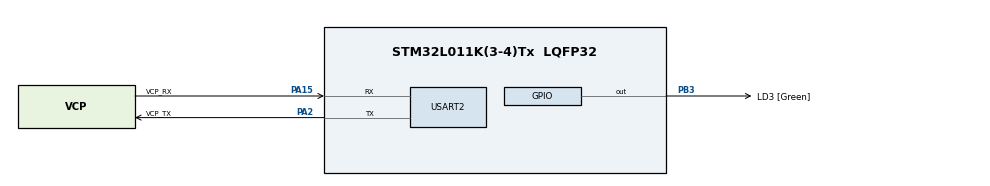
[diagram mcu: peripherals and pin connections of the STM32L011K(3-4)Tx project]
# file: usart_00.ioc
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Dma.Request0=USART2_RX
Dma.Request1=USART2_TX
Dma.USART2_RX.0.Direction=DMA_PERIPH_TO_MEMORY
Dma.USART2_RX.0.Instance=DMA1_Channel3
Dma.USART2_RX.0.MemDataAlignment=DMA_MDATAALIGN_BYTE
Dma.USART2_RX.0.MemInc=DMA_MINC_ENABLE
Dma.USART2_RX.0.Mode=DMA_NORMAL
Dma.USART2_RX.0.PeriphDataAlignment=DMA_PDATAALIGN_BYTE
Dma.USART2_RX.0.PeriphInc=DMA_PINC_DISABLE
Dma.USART2_RX.0.Priority=DMA_PRIORITY_LOW
Dma.USART2_TX.1.Direction=DMA_MEMORY_TO_PERIPH
Dma.USART2_TX.1.Instance=DMA1_Channel2
Dma.USART2_TX.1.MemDataAlignment=DMA_MDATAALIGN_BYTE
Dma.USART2_TX.1.MemInc=DMA_MINC_ENABLE
Dma.USART2_TX.1.Mode=DMA_NORMAL
Dma.USART2_TX.1.PeriphDataAlignment=DMA_PDATAALIGN_BYTE
Dma.USART2_TX.1.PeriphInc=DMA_PINC_DISABLE
Dma.USART2_TX.1.Priority=DMA_PRIORITY_LOW
Mcu.Family=STM32L0
Mcu.Name=STM32L011K(3-4)Tx
Mcu.Package=LQFP32
NVIC.DMA1_Channel2_3_IRQn=true\:0\:0\:false\:false\:true\:false
PA13.GPIO_Label=TMS
PA13.Mode=Serial_Wire
PA13.Signal=SYS_SWDIO
PA14.GPIO_Label=TCK
PA14.Mode=Serial_Wire
PA14.Signal=SYS_SWCLK
PA15.GPIO_Label=VCP_RX
PA15.Mode=Asynchronous
PA15.Signal=USART2_RX
PA2.GPIO_Label=VCP_TX
PA2.Mode=Asynchronous
PA2.Signal=USART2_TX
PB3.GPIO_Label=LD3 [Green]
PB3.Signal=GPIO_Output
PC14-OSC32_IN.Mode=LSE-External-Oscillator
PC14-OSC32_IN.Signal=RCC_OSC32_IN
PC15-OSC32_OUT.Mode=LSE-External-Oscillator
PC15-OSC32_OUT.Signal=RCC_OSC32_OUT
ProjectManager.HeapSize=0x200
ProjectManager.StackSize=0x400
ProjectManager.TargetToolchain=Makefile
RCC.AHBFreq_Value=4194000
RCC.APB1Freq_Value=4194000
RCC.APB1TimFreq_Value=4194000
RCC.APB2Freq_Value=4194000
RCC.APB2TimFreq_Value=4194000
RCC.HCLKFreq_Value=4194000
RCC.HSE_VALUE=8000000
RCC.HSI16_VALUE=16000000
RCC.HSI48_VALUE=48000000
RCC.HSI_VALUE=16000000
RCC.MSIClockRange=RCC_MSIRANGE_6
RCC.MSI_VALUE=4194000
RCC.PLLMUL=RCC_PLLMUL_4
RCC.SYSCLKFreq_VALUE=4194000
RCC.VCOOutputFreq_Value=64000000
USART2.VirtualMode-Asynchronous=VM_ASYNC
board=NUCLEO-L011K4

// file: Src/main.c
/**
  ******************************************************************************
  * @file           : main.c
  * @brief          : Main program body
  ******************************************************************************
  ** This notice applies to any and all portions of this file
  * that are not between comment pairs USER CODE BEGIN and
  * USER CODE END. Other portions of this file, whether
  * inserted by the user or by software development tools
  * are owned by their respective copyright owners.
  *
  * COPYRIGHT(c) 2018 STMicroelectronics
  *
  * Redistribution and use in source and binary forms, with or without modification,
  * are permitted provided that the following conditions are met:
  *   1. Redistributions of source code must retain the above copyright notice,
  *      this list of conditions and the following disclaimer.
  *   2. Redistributions in binary form must reproduce the above copyright notice,
  *      this list of conditions and the following disclaimer in the documentation
  *      and/or other materials provided with the distribution.
  *   3. Neither the name of STMicroelectronics nor the names of its contributors
  *      may be used to endorse or promote products derived from this software
  *      without specific prior written permission.
  *
  * THIS SOFTWARE IS PROVIDED BY THE COPYRIGHT HOLDERS AND CONTRIBUTORS "AS IS"
  * AND ANY EXPRESS OR IMPLIED WARRANTIES, INCLUDING, BUT NOT LIMITED TO, THE
  * IMPLIED WARRANTIES OF MERCHANTABILITY AND FITNESS FOR A PARTICULAR PURPOSE ARE
  * DISCLAIMED. IN NO EVENT SHALL THE COPYRIGHT HOLDER OR CONTRIBUTORS BE LIABLE
  * FOR ANY DIRECT, INDIRECT, INCIDENTAL, SPECIAL, EXEMPLARY, OR CONSEQUENTIAL
  * DAMAGES (INCLUDING, BUT NOT LIMITED TO, PROCUREMENT OF SUBSTITUTE GOODS OR
  * SERVICES; LOSS OF USE, DATA, OR PROFITS; OR BUSINESS INTERRUPTION) HOWEVER
  * CAUSED AND ON ANY THEORY OF LIABILITY, WHETHER IN CONTRACT, STRICT LIABILITY,
  * OR TORT (INCLUDING NEGLIGENCE OR OTHERWISE) ARISING IN ANY WAY OUT OF THE USE
  * OF THIS SOFTWARE, EVEN IF ADVISED OF THE POSSIBILITY OF SUCH DAMAGE.
  *
  ******************************************************************************
  */
#include "main.h"

/* USER CODE BEGIN Includes */
#include "stdlib.h"
#include "string.h"
#include "tinyprintf.h"
/* USER CODE END Includes */

/* USER CODE BEGIN PV */
/* Private variables ---------------------------------------------------------*/
//uint8_t *str;
//uint32_t size_of_str;
/* USER CODE END PV */

static void LL_Init(void);
void SystemClock_Config(void);
static void MX_GPIO_Init(void);
static void MX_DMA_Init(void);
static void MX_USART2_UART_Init(void);

/* USER CODE BEGIN PFP */
/* Private function prototypes -----------------------------------------------*/
/* USER CODE END PFP */

int main(void)
{

  /* MCU Configuration----------------------------------------------------------*/

  /* Reset of all peripherals, Initializes the Flash interface and the Systick. */
  LL_Init();

  /* Configure the system clock */
  SystemClock_Config();

  /* Initialize all configured peripherals */
  MX_GPIO_Init();
  MX_DMA_Init();
  MX_USART2_UART_Init();
  /* USER CODE BEGIN 2 */
  uart_print_init();
  tfp_printf ("tfp_printf testing..!!\n");
  uint32_t a = 100;
  tfp_printf ("Int : %d, Hex : %04x\n", a ,a);
  /* USER CODE END 2 */

  /* Infinite loop */
  /* USER CODE BEGIN WHILE */
  while (1)
  {
//    tfp_printf("In while 1.. Code not stuck..!!\n");
  /* USER CODE END WHILE */

  }

}
static void LL_Init(void)
{

  LL_APB2_GRP1_EnableClock(LL_APB2_GRP1_PERIPH_SYSCFG);
  LL_APB1_GRP1_EnableClock(LL_APB1_GRP1_PERIPH_PWR);

  /* System interrupt init*/
  /* SVC_IRQn interrupt configuration */
  NVIC_SetPriority(SVC_IRQn, 0);
  /* PendSV_IRQn interrupt configuration */
  NVIC_SetPriority(PendSV_IRQn, 0);
  /* SysTick_IRQn interrupt configuration */
  NVIC_SetPriority(SysTick_IRQn, 0);

}

void SystemClock_Config(void)
{

  LL_FLASH_SetLatency(LL_FLASH_LATENCY_0);

  if(LL_FLASH_GetLatency() != LL_FLASH_LATENCY_0)
  {
  Error_Handler();
  }
  LL_PWR_SetRegulVoltageScaling(LL_PWR_REGU_VOLTAGE_SCALE1);

  LL_RCC_MSI_Enable();

   /* Wait till MSI is ready */
  while(LL_RCC_MSI_IsReady() != 1)
  {

  }
  LL_RCC_MSI_SetRange(LL_RCC_MSIRANGE_6);

  LL_RCC_MSI_SetCalibTrimming(0);

  LL_RCC_SetAHBPrescaler(LL_RCC_SYSCLK_DIV_1);

  LL_RCC_SetAPB1Prescaler(LL_RCC_APB1_DIV_1);

  LL_RCC_SetAPB2Prescaler(LL_RCC_APB2_DIV_1);

  LL_RCC_SetSysClkSource(LL_RCC_SYS_CLKSOURCE_MSI);

   /* Wait till System clock is ready */
  while(LL_RCC_GetSysClkSource() != LL_RCC_SYS_CLKSOURCE_STATUS_MSI)
  {

  }
  LL_Init1msTick(4194000);

  LL_SYSTICK_SetClkSource(LL_SYSTICK_CLKSOURCE_HCLK);

  LL_SetSystemCoreClock(4194000);

  LL_RCC_SetUSARTClockSource(LL_RCC_USART2_CLKSOURCE_PCLK1);

  /* SysTick_IRQn interrupt configuration */
  NVIC_SetPriority(SysTick_IRQn, 0);
}

/* USART2 init function */
static void MX_USART2_UART_Init(void)
{

  LL_USART_InitTypeDef USART_InitStruct;

  LL_GPIO_InitTypeDef GPIO_InitStruct;

  /* Peripheral clock enable */
  LL_APB1_GRP1_EnableClock(LL_APB1_GRP1_PERIPH_USART2);

  /**USART2 GPIO Configuration
  PA2   ------> USART2_TX
  PA15   ------> USART2_RX
  */
  GPIO_InitStruct.Pin = VCP_TX_Pin;
  GPIO_InitStruct.Mode = LL_GPIO_MODE_ALTERNATE;
  GPIO_InitStruct.Speed = LL_GPIO_SPEED_FREQ_VERY_HIGH;
  GPIO_InitStruct.OutputType = LL_GPIO_OUTPUT_PUSHPULL;
  GPIO_InitStruct.Pull = LL_GPIO_PULL_NO;
  GPIO_InitStruct.Alternate = LL_GPIO_AF_4;
  LL_GPIO_Init(VCP_TX_GPIO_Port, &GPIO_InitStruct);

  GPIO_InitStruct.Pin = VCP_RX_Pin;
  GPIO_InitStruct.Mode = LL_GPIO_MODE_ALTERNATE;
  GPIO_InitStruct.Speed = LL_GPIO_SPEED_FREQ_VERY_HIGH;
  GPIO_InitStruct.OutputType = LL_GPIO_OUTPUT_PUSHPULL;
  GPIO_InitStruct.Pull = LL_GPIO_PULL_NO;
  GPIO_InitStruct.Alternate = LL_GPIO_AF_4;
  LL_GPIO_Init(VCP_RX_GPIO_Port, &GPIO_InitStruct);

  /* USART2 DMA Init */

  /* USART2_RX Init */
  LL_DMA_SetPeriphRequest(DMA1, LL_DMA_CHANNEL_3, LL_DMA_REQUEST_4);

  LL_DMA_SetDataTransferDirection(DMA1, LL_DMA_CHANNEL_3, LL_DMA_DIRECTION_PERIPH_TO_MEMORY);

  LL_DMA_SetChannelPriorityLevel(DMA1, LL_DMA_CHANNEL_3, LL_DMA_PRIORITY_LOW);

  LL_DMA_SetMode(DMA1, LL_DMA_CHANNEL_3, LL_DMA_MODE_NORMAL);

  LL_DMA_SetPeriphIncMode(DMA1, LL_DMA_CHANNEL_3, LL_DMA_PERIPH_NOINCREMENT);

  LL_DMA_SetMemoryIncMode(DMA1, LL_DMA_CHANNEL_3, LL_DMA_MEMORY_INCREMENT);

  LL_DMA_SetPeriphSize(DMA1, LL_DMA_CHANNEL_3, LL_DMA_PDATAALIGN_BYTE);

  LL_DMA_SetMemorySize(DMA1, LL_DMA_CHANNEL_3, LL_DMA_MDATAALIGN_BYTE);

  /* USART2_TX Init */
  LL_DMA_SetPeriphRequest(DMA1, LL_DMA_CHANNEL_2, LL_DMA_REQUEST_4);

  LL_DMA_SetDataTransferDirection(DMA1, LL_DMA_CHANNEL_2, LL_DMA_DIRECTION_MEMORY_TO_PERIPH);

  LL_DMA_SetChannelPriorityLevel(DMA1, LL_DMA_CHANNEL_2, LL_DMA_PRIORITY_LOW);

  LL_DMA_SetMode(DMA1, LL_DMA_CHANNEL_2, LL_DMA_MODE_NORMAL);

  LL_DMA_SetPeriphIncMode(DMA1, LL_DMA_CHANNEL_2, LL_DMA_PERIPH_NOINCREMENT);

  LL_DMA_SetMemoryIncMode(DMA1, LL_DMA_CHANNEL_2, LL_DMA_MEMORY_INCREMENT);

  LL_DMA_SetPeriphSize(DMA1, LL_DMA_CHANNEL_2, LL_DMA_PDATAALIGN_BYTE);

  LL_DMA_SetMemorySize(DMA1, LL_DMA_CHANNEL_2, LL_DMA_MDATAALIGN_BYTE);

  USART_InitStruct.BaudRate = 115200;
  USART_InitStruct.DataWidth = LL_USART_DATAWIDTH_8B;
  USART_InitStruct.StopBits = LL_USART_STOPBITS_1;
  USART_InitStruct.Parity = LL_USART_PARITY_NONE;
  USART_InitStruct.TransferDirection = LL_USART_DIRECTION_TX_RX;
  USART_InitStruct.HardwareFlowControl = LL_USART_HWCONTROL_NONE;
  USART_InitStruct.OverSampling = LL_USART_OVERSAMPLING_16;
  LL_USART_Init(USART2, &USART_InitStruct);

  LL_USART_DisableOverrunDetect(USART2);

  LL_USART_ConfigAsyncMode(USART2);

  LL_USART_Enable(USART2);

}

static void MX_DMA_Init(void)
{
  /* Init with LL driver */
  /* DMA controller clock enable */
  LL_AHB1_GRP1_EnableClock(LL_AHB1_GRP1_PERIPH_DMA1);

  /* DMA interrupt init */
  /* DMA1_Channel2_3_IRQn interrupt configuration */
  NVIC_SetPriority(DMA1_Channel2_3_IRQn, 0);
  NVIC_EnableIRQ(DMA1_Channel2_3_IRQn);

}

/** Configure pins as
        * Analog
        * Input
        * Output
        * EVENT_OUT
        * EXTI
*/
static void MX_GPIO_Init(void)
{

  LL_GPIO_InitTypeDef GPIO_InitStruct;

  /* GPIO Ports Clock Enable */
  LL_IOP_GRP1_EnableClock(LL_IOP_GRP1_PERIPH_GPIOC);
  LL_IOP_GRP1_EnableClock(LL_IOP_GRP1_PERIPH_GPIOA);
  LL_IOP_GRP1_EnableClock(LL_IOP_GRP1_PERIPH_GPIOB);

  /**/
  LL_GPIO_ResetOutputPin(LD3_GPIO_Port, LD3_Pin);

  /**/
  GPIO_InitStruct.Pin = LD3_Pin;
  GPIO_InitStruct.Mode = LL_GPIO_MODE_OUTPUT;
  GPIO_InitStruct.Speed = LL_GPIO_SPEED_FREQ_LOW;
  GPIO_InitStruct.OutputType = LL_GPIO_OUTPUT_PUSHPULL;
  GPIO_InitStruct.Pull = LL_GPIO_PULL_NO;
  LL_GPIO_Init(LD3_GPIO_Port, &GPIO_InitStruct);

}

void _Error_Handler(char *file, int line)
{
  while(1)
  {
  }
}

/************************ (C) COPYRIGHT STMicroelectronics *****END OF FILE****/
